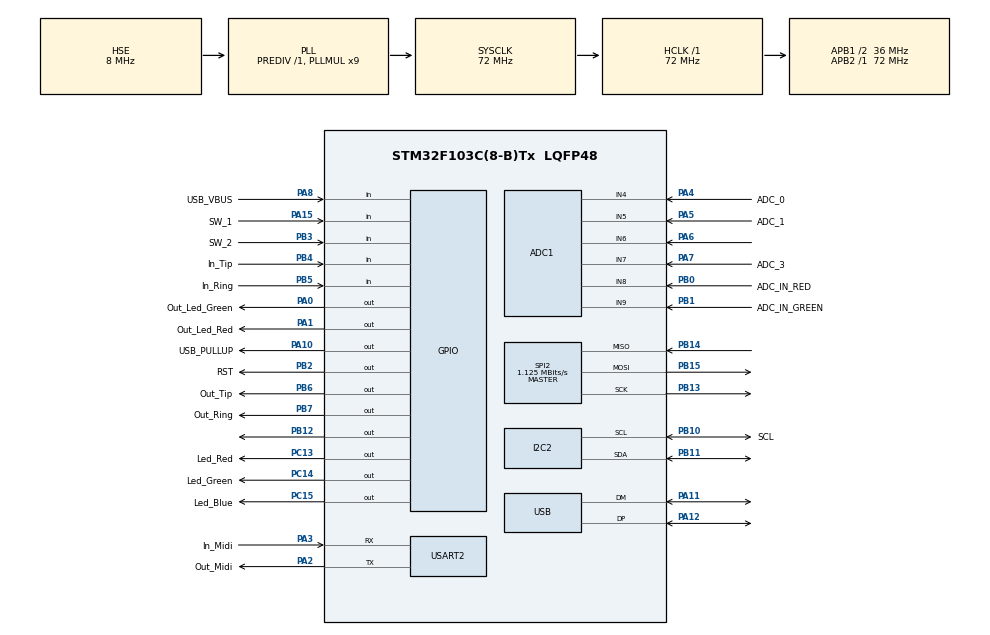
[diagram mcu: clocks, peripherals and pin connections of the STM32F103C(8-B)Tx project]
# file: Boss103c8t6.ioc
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Mcu.Family=STM32F1
USB_DEVICE.CLASS_NAME_FS=CDC
SPI2.VirtualType=VM_MASTER
PB10.Mode=I2C
ADC1.ContinuousConvMode=ENABLE
ADC1.SamplingTime-6\#ChannelRegularConversion=ADC_SAMPLETIME_239CYCLES_5
PA14.GPIO_Label=swdclk
PA11.Mode=Device
PB0.GPIO_Label=ADC_IN_RED
PB6.GPIO_Label=Out_Tip
PB11.Signal=I2C2_SDA
PB13.Signal=SPI2_SCK
PB15.Signal=SPI2_MOSI
PC15-OSC32_OUT.GPIO_Label=Led_Blue
RCC.SYSCLKSource=RCC_SYSCLKSOURCE_PLLCLK
ProjectManager.StackSize=0x400
PD1-OSC_OUT.Signal=RCC_OSC_OUT
PA15.GPIO_Label=SW_1
PA12.Signal=USB_DP
ADC1.Channel-5\#ChannelRegularConversion=ADC_CHANNEL_8
PA10.PinState=GPIO_PIN_SET
ADC1.Channel-3\#ChannelRegularConversion=ADC_CHANNEL_6
RCC.HCLKFreq_Value=72000000
RCC.APB2TimFreq_Value=72000000
PB6.Signal=GPIO_Output
Dma.ADC1.0.Direction=DMA_PERIPH_TO_MEMORY
ADC1.Channel-2\#ChannelRegularConversion=ADC_CHANNEL_5
Dma.ADC1.0.MemDataAlignment=DMA_MDATAALIGN_HALFWORD
RCC.AHBFreq_Value=72000000
SPI2.BaudRatePrescaler=SPI_BAUDRATEPRESCALER_32
PB2.Signal=GPIO_Output
RCC.PLLMUL=RCC_PLL_MUL9
ADC1.SamplingTime-4\#ChannelRegularConversion=ADC_SAMPLETIME_239CYCLES_5
ADC1.Channel-6\#ChannelRegularConversion=ADC_CHANNEL_9
PB3.GPIO_PuPd=GPIO_PULLUP
ADC1.Rank-2\#ChannelRegularConversion=2
PA14.Mode=Serial_Wire
PB14.Mode=Full_Duplex_Master
PB1.GPIO_Label=ADC_IN_GREEN
Dma.ADC1.0.PeriphInc=DMA_PINC_DISABLE
PA10.GPIO_Label=USB_PULLUP
SH.ADCx_IN8.0=ADC1_IN8,IN8
SPI2.CalculateBaudRate=1.125 MBits/s
PB7.Signal=GPIO_Output
PA8.Signal=GPIO_Input
TIM4.Period=65535
PB7.GPIO_Label=Out_Ring
Mcu.Package=LQFP48
PB1.Signal=ADCx_IN9
PA6.Signal=ADCx_IN6
SPI2.Mode=SPI_MODE_MASTER
USART2.VirtualMode=VM_ASYNC
PC13-TAMPER-RTC.GPIO_PuPd=GPIO_PULLUP
PA2.GPIO_Label=Out_Midi
PA10.Signal=GPIO_Output
PA15.Signal=GPIO_Input
SH.ADCx_IN9.0=ADC1_IN9,IN9
PB5.GPIO_Label=In_Ring
PC15-OSC32_OUT.GPIO_ModeDefaultOutputPP=GPIO_MODE_OUTPUT_OD
PC14-OSC32_IN.GPIO_ModeDefaultOutputPP=GPIO_MODE_OUTPUT_OD
RCC.APB1TimFreq_Value=72000000
PC14-OSC32_IN.GPIO_Label=Led_Green
SPI2.Direction=SPI_DIRECTION_2LINES
PB13.Mode=Full_Duplex_Master
ADC1.Rank-6\#ChannelRegularConversion=6
Dma.Request0=ADC1
PA4.GPIO_Label=ADC_0
ADC1.Rank-4\#ChannelRegularConversion=4
PB4.Signal=GPIO_Input
PA3.Signal=USART2_RX
PB3.GPIO_Label=SW_2
Dma.ADC1.0.Instance=DMA1_Channel1
PD1-OSC_OUT.Mode=HSE-External-Oscillator
ADC1.Channel-4\#ChannelRegularConversion=ADC_CHANNEL_7
USB_DEVICE.VirtualModeFS=Cdc_FS
SH.ADCx_IN6.0=ADC1_IN6,IN6
PC13-TAMPER-RTC.Signal=GPIO_Output
RCC.USBPrescaler=RCC_USBCLKSOURCE_PLL_DIV1_5
PD0-OSC_IN.Signal=RCC_OSC_IN
RCC.APB1CLKDivider=RCC_HCLK_DIV2
PC14-OSC32_IN.Signal=GPIO_Output
ADC1.SamplingTime-2\#ChannelRegularConversion=ADC_SAMPLETIME_239CYCLES_5
PA0-WKUP.GPIO_Label=Out_Led_Green
PA0-WKUP.Signal=GPIO_Output
RCC.ADCPresc=RCC_ADCPCLK2_DIV6
PA3.Mode=Asynchronous
PA13.Signal=SYS_JTMS-SWDIO
Dma.ADC1.0.PeriphDataAlignment=DMA_PDATAALIGN_HALFWORD
PA8.GPIO_Label=USB_VBUS
PB11.Mode=I2C
ProjectManager.TargetToolchain=STM32CubeIDE
PB10.GPIO_Label=SCL
SH.ADCx_IN7.0=ADC1_IN7,IN7
Dma.ADC1.0.Mode=DMA_CIRCULAR
VP_USB_DEVICE_VS_USB_DEVICE_CDC_FS.Mode=CDC_FS
Dma.ADC1.0.Priority=DMA_PRIORITY_LOW
ADC1.Channel-1\#ChannelRegularConversion=ADC_CHANNEL_4
RCC.USBFreq_Value=48000000
TIM4.Prescaler=35999
PC15-OSC32_OUT.Signal=GPIO_Output
PA1.Signal=GPIO_Output
PD0-OSC_IN.Mode=HSE-External-Oscillator
PB10.Signal=I2C2_SCL
PB14.Signal=SPI2_MISO
PA5.Signal=ADCx_IN5
board=custom
PC13-TAMPER-RTC.GPIO_Label=Led_Red
PB15.Mode=Full_Duplex_Master
RCC.APB2Freq_Value=72000000
PB4.GPIO_Label=In_Tip
NVIC.USB_LP_CAN1_RX0_IRQn=true\:0\:0\:false\:false\:true\:false\:true
PA1.GPIO_Label=Out_Led_Red
SH.ADCx_IN4.0=ADC1_IN4,IN4
PC15-OSC32_OUT.GPIO_PuPd=GPIO_PULLUP
ADC1.NbrOfConversion=6
PA13.Mode=Serial_Wire
Mcu.Name=STM32F103C(8-B)Tx
PA2.Signal=USART2_TX
PA13.GPIO_Label=swdio
PB3.Signal=GPIO_Input
PA4.Signal=ADCx_IN4
ADC1.SamplingTime-1\#ChannelRegularConversion=ADC_SAMPLETIME_239CYCLES_5
RCC.SYSCLKFreq_VALUE=72000000
PC13-TAMPER-RTC.GPIO_ModeDefaultOutputPP=GPIO_MODE_OUTPUT_OD
PB5.Signal=GPIO_Input
PA7.GPIO_Label=ADC_3
ADC1.master=1
PA12.Mode=Device
PA5.GPIO_Label=ADC_1
ADC1.Rank-3\#ChannelRegularConversion=3
ADC1.SamplingTime-3\#ChannelRegularConversion=ADC_SAMPLETIME_239CYCLES_5
ADC1.Rank-1\#ChannelRegularConversion=1
PA11.Signal=USB_DM
PA14.Signal=SYS_JTCK-SWCLK
Dma.ADC1.0.MemInc=DMA_MINC_ENABLE
PB2.GPIO_Label=RST
ProjectManager.HeapSize=0x200
ADC1.SamplingTime-5\#ChannelRegularConversion=ADC_SAMPLETIME_239CYCLES_5
SH.ADCx_IN5.0=ADC1_IN5,IN5
VP_TIM4_VS_ClockSourceINT.Mode=Internal
NVIC.PriorityGroup=NVIC_PRIORITYGROUP_4
ADC1.NbrOfConversionFlag=1
PA15.GPIO_PuPd=GPIO_PULLUP
PA2.Mode=Asynchronous
PC14-OSC32_IN.GPIO_PuPd=GPIO_PULLUP
NVIC.DMA1_Channel1_IRQn=true\:0\:0\:false\:false\:true\:false\:true
ADC1.DataAlign=ADC_DATAALIGN_LEFT
RCC.APB1Freq_Value=36000000
PB0.Signal=ADCx_IN8
USB_DEVICE.VirtualMode=Cdc
ADC1.Rank-5\#ChannelRegularConversion=5
PB12.Signal=GPIO_Output
PA3.GPIO_Label=In_Midi
PA7.Signal=ADCx_IN7

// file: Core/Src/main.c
/* USER CODE BEGIN Header */
/**
  ******************************************************************************
  * @file           : main.c
  * @brief          : Main program body
  ******************************************************************************
  * @attention
  *
  * <h2><center>&copy; Copyright (c) 2023 STMicroelectronics.
  * All rights reserved.</center></h2>
  *
  * This software component is licensed by ST under Ultimate Liberty license
  * SLA0044, the "License"; You may not use this file except in compliance with
  * the License. You may obtain a copy of the License at:
  *                             www.st.com/SLA0044
  *
  ******************************************************************************
  */
/* USER CODE END Header */
#include "main.h"
#include "usb_device.h"

/* USER CODE BEGIN Includes */
#include "ProjectMain.h"
/* USER CODE END Includes */

ADC_HandleTypeDef hadc1;
DMA_HandleTypeDef hdma_adc1;

I2C_HandleTypeDef hi2c2;

SPI_HandleTypeDef hspi2;

TIM_HandleTypeDef htim4;

UART_HandleTypeDef huart2;

void SystemClock_Config(void);
static void MX_GPIO_Init(void);
static void MX_DMA_Init(void);
static void MX_USART2_UART_Init(void);
static void MX_ADC1_Init(void);
static void MX_SPI2_Init(void);
static void MX_I2C2_Init(void);
static void MX_TIM4_Init(void);

int main(void)
{

  /* MCU Configuration--------------------------------------------------------*/

  /* Reset of all peripherals, Initializes the Flash interface and the Systick. */
  HAL_Init();

  /* Configure the system clock */
  SystemClock_Config();

  /* Initialize all configured peripherals */
  MX_GPIO_Init();
  MX_DMA_Init();
  MX_USART2_UART_Init();
  MX_ADC1_Init();
  MX_SPI2_Init();
  MX_USB_DEVICE_Init();
  MX_I2C2_Init();
  MX_TIM4_Init();
  /* USER CODE BEGIN 2 */
  while(HAL_ADCEx_Calibration_Start(&hadc1) != HAL_OK);							// калибровка и запуск АЦП
  HAL_ADC_Start_DMA(&hadc1, (uint32_t *) Adc1ConvertedValue, ADC_NUM_CHANNELS);
  ProjectMain();																// Основной цикл
  /* USER CODE END 2 */

  /* Infinite loop */
  while (1)
  {

  }
}

void SystemClock_Config(void)
{
  RCC_OscInitTypeDef RCC_OscInitStruct = {0};
  RCC_ClkInitTypeDef RCC_ClkInitStruct = {0};
  RCC_PeriphCLKInitTypeDef PeriphClkInit = {0};

  /** Initializes the RCC Oscillators according to the specified parameters
  * in the RCC_OscInitTypeDef structure.
  */
  RCC_OscInitStruct.OscillatorType = RCC_OSCILLATORTYPE_HSE;
  RCC_OscInitStruct.HSEState = RCC_HSE_ON;
  RCC_OscInitStruct.HSEPredivValue = RCC_HSE_PREDIV_DIV1;
  RCC_OscInitStruct.HSIState = RCC_HSI_ON;
  RCC_OscInitStruct.PLL.PLLState = RCC_PLL_ON;
  RCC_OscInitStruct.PLL.PLLSource = RCC_PLLSOURCE_HSE;
  RCC_OscInitStruct.PLL.PLLMUL = RCC_PLL_MUL9;
  if (HAL_RCC_OscConfig(&RCC_OscInitStruct) != HAL_OK)
  {
    Error_Handler();
  }
  /** Initializes the CPU, AHB and APB buses clocks
  */
  RCC_ClkInitStruct.ClockType = RCC_CLOCKTYPE_HCLK|RCC_CLOCKTYPE_SYSCLK
                              |RCC_CLOCKTYPE_PCLK1|RCC_CLOCKTYPE_PCLK2;
  RCC_ClkInitStruct.SYSCLKSource = RCC_SYSCLKSOURCE_PLLCLK;
  RCC_ClkInitStruct.AHBCLKDivider = RCC_SYSCLK_DIV1;
  RCC_ClkInitStruct.APB1CLKDivider = RCC_HCLK_DIV2;
  RCC_ClkInitStruct.APB2CLKDivider = RCC_HCLK_DIV1;

  if (HAL_RCC_ClockConfig(&RCC_ClkInitStruct, FLASH_LATENCY_2) != HAL_OK)
  {
    Error_Handler();
  }
  PeriphClkInit.PeriphClockSelection = RCC_PERIPHCLK_ADC|RCC_PERIPHCLK_USB;
  PeriphClkInit.AdcClockSelection = RCC_ADCPCLK2_DIV6;
  PeriphClkInit.UsbClockSelection = RCC_USBCLKSOURCE_PLL_DIV1_5;
  if (HAL_RCCEx_PeriphCLKConfig(&PeriphClkInit) != HAL_OK)
  {
    Error_Handler();
  }
}

static void MX_ADC1_Init(void)
{

  ADC_ChannelConfTypeDef sConfig = {0};

  /** Common config
  */
  hadc1.Instance = ADC1;
  hadc1.Init.ScanConvMode = ADC_SCAN_ENABLE;
  hadc1.Init.ContinuousConvMode = ENABLE;
  hadc1.Init.DiscontinuousConvMode = DISABLE;
  hadc1.Init.ExternalTrigConv = ADC_SOFTWARE_START;
  hadc1.Init.DataAlign = ADC_DATAALIGN_LEFT;
  hadc1.Init.NbrOfConversion = 6;
  if (HAL_ADC_Init(&hadc1) != HAL_OK)
  {
    Error_Handler();
  }
  /** Configure Regular Channel
  */
  sConfig.Channel = ADC_CHANNEL_4;
  sConfig.Rank = ADC_REGULAR_RANK_1;
  sConfig.SamplingTime = ADC_SAMPLETIME_239CYCLES_5;
  if (HAL_ADC_ConfigChannel(&hadc1, &sConfig) != HAL_OK)
  {
    Error_Handler();
  }
  /** Configure Regular Channel
  */
  sConfig.Channel = ADC_CHANNEL_5;
  sConfig.Rank = ADC_REGULAR_RANK_2;
  if (HAL_ADC_ConfigChannel(&hadc1, &sConfig) != HAL_OK)
  {
    Error_Handler();
  }
  /** Configure Regular Channel
  */
  sConfig.Channel = ADC_CHANNEL_6;
  sConfig.Rank = ADC_REGULAR_RANK_3;
  if (HAL_ADC_ConfigChannel(&hadc1, &sConfig) != HAL_OK)
  {
    Error_Handler();
  }
  /** Configure Regular Channel
  */
  sConfig.Channel = ADC_CHANNEL_7;
  sConfig.Rank = ADC_REGULAR_RANK_4;
  if (HAL_ADC_ConfigChannel(&hadc1, &sConfig) != HAL_OK)
  {
    Error_Handler();
  }
  /** Configure Regular Channel
  */
  sConfig.Channel = ADC_CHANNEL_8;
  sConfig.Rank = ADC_REGULAR_RANK_5;
  if (HAL_ADC_ConfigChannel(&hadc1, &sConfig) != HAL_OK)
  {
    Error_Handler();
  }
  /** Configure Regular Channel
  */
  sConfig.Channel = ADC_CHANNEL_9;
  sConfig.Rank = ADC_REGULAR_RANK_6;
  if (HAL_ADC_ConfigChannel(&hadc1, &sConfig) != HAL_OK)
  {
    Error_Handler();
  }

}

static void MX_I2C2_Init(void)
{

  hi2c2.Instance = I2C2;
  hi2c2.Init.ClockSpeed = 100000;
  hi2c2.Init.DutyCycle = I2C_DUTYCYCLE_2;
  hi2c2.Init.OwnAddress1 = 0;
  hi2c2.Init.AddressingMode = I2C_ADDRESSINGMODE_7BIT;
  hi2c2.Init.DualAddressMode = I2C_DUALADDRESS_DISABLE;
  hi2c2.Init.OwnAddress2 = 0;
  hi2c2.Init.GeneralCallMode = I2C_GENERALCALL_DISABLE;
  hi2c2.Init.NoStretchMode = I2C_NOSTRETCH_DISABLE;
  if (HAL_I2C_Init(&hi2c2) != HAL_OK)
  {
    Error_Handler();
  }

}

static void MX_SPI2_Init(void)
{

  /* SPI2 parameter configuration*/
  hspi2.Instance = SPI2;
  hspi2.Init.Mode = SPI_MODE_MASTER;
  hspi2.Init.Direction = SPI_DIRECTION_2LINES;
  hspi2.Init.DataSize = SPI_DATASIZE_8BIT;
  hspi2.Init.CLKPolarity = SPI_POLARITY_LOW;
  hspi2.Init.CLKPhase = SPI_PHASE_1EDGE;
  hspi2.Init.NSS = SPI_NSS_SOFT;
  hspi2.Init.BaudRatePrescaler = SPI_BAUDRATEPRESCALER_32;
  hspi2.Init.FirstBit = SPI_FIRSTBIT_MSB;
  hspi2.Init.TIMode = SPI_TIMODE_DISABLE;
  hspi2.Init.CRCCalculation = SPI_CRCCALCULATION_DISABLE;
  hspi2.Init.CRCPolynomial = 10;
  if (HAL_SPI_Init(&hspi2) != HAL_OK)
  {
    Error_Handler();
  }

}

static void MX_TIM4_Init(void)
{

  TIM_ClockConfigTypeDef sClockSourceConfig = {0};
  TIM_MasterConfigTypeDef sMasterConfig = {0};

  htim4.Instance = TIM4;
  htim4.Init.Prescaler = 35999;
  htim4.Init.CounterMode = TIM_COUNTERMODE_UP;
  htim4.Init.Period = 65535;
//  htim4.Init.Period = 65533;
  htim4.Init.ClockDivision = TIM_CLOCKDIVISION_DIV1;
  htim4.Init.AutoReloadPreload = TIM_AUTORELOAD_PRELOAD_DISABLE;
  if (HAL_TIM_Base_Init(&htim4) != HAL_OK)
  {
    Error_Handler();
  }
  sClockSourceConfig.ClockSource = TIM_CLOCKSOURCE_INTERNAL;
  if (HAL_TIM_ConfigClockSource(&htim4, &sClockSourceConfig) != HAL_OK)
  {
    Error_Handler();
  }
  sMasterConfig.MasterOutputTrigger = TIM_TRGO_RESET;
  sMasterConfig.MasterSlaveMode = TIM_MASTERSLAVEMODE_DISABLE;
  if (HAL_TIMEx_MasterConfigSynchronization(&htim4, &sMasterConfig) != HAL_OK)
  {
    Error_Handler();
  }

}

static void MX_USART2_UART_Init(void)
{

  huart2.Instance = USART2;
  huart2.Init.BaudRate = 115200;
  huart2.Init.WordLength = UART_WORDLENGTH_8B;
  huart2.Init.StopBits = UART_STOPBITS_1;
  huart2.Init.Parity = UART_PARITY_NONE;
  huart2.Init.Mode = UART_MODE_TX_RX;
  huart2.Init.HwFlowCtl = UART_HWCONTROL_NONE;
  huart2.Init.OverSampling = UART_OVERSAMPLING_16;
  if (HAL_UART_Init(&huart2) != HAL_OK)
  {
    Error_Handler();
  }

}

static void MX_DMA_Init(void)
{

  /* DMA controller clock enable */
  __HAL_RCC_DMA1_CLK_ENABLE();

  /* DMA interrupt init */
  /* DMA1_Channel1_IRQn interrupt configuration */
  HAL_NVIC_SetPriority(DMA1_Channel1_IRQn, 0, 0);
  HAL_NVIC_EnableIRQ(DMA1_Channel1_IRQn);

}

static void MX_GPIO_Init(void)
{
  GPIO_InitTypeDef GPIO_InitStruct = {0};

  /* GPIO Ports Clock Enable */
  __HAL_RCC_GPIOC_CLK_ENABLE();
  __HAL_RCC_GPIOD_CLK_ENABLE();
  __HAL_RCC_GPIOA_CLK_ENABLE();
  __HAL_RCC_GPIOB_CLK_ENABLE();

  /*Configure GPIO pin Output Level */
  HAL_GPIO_WritePin(GPIOC, Led_Red_Pin|Led_Green_Pin|Led_Blue_Pin, GPIO_PIN_RESET);

  /*Configure GPIO pin Output Level */
  HAL_GPIO_WritePin(GPIOA, Out_Led_Green_Pin|Out_Led_Red_Pin, GPIO_PIN_RESET);

  /*Configure GPIO pin Output Level */
  HAL_GPIO_WritePin(GPIOB, RST_Pin|GPIO_PIN_12|Out_Tip_Pin|Out_Ring_Pin, GPIO_PIN_RESET);

  /*Configure GPIO pin Output Level */
  HAL_GPIO_WritePin(USB_PULLUP_GPIO_Port, USB_PULLUP_Pin, GPIO_PIN_SET);

  /*Configure GPIO pins : Led_Red_Pin Led_Green_Pin Led_Blue_Pin */
  GPIO_InitStruct.Pin = Led_Red_Pin|Led_Green_Pin|Led_Blue_Pin;
  GPIO_InitStruct.Mode = GPIO_MODE_OUTPUT_OD;
  GPIO_InitStruct.Pull = GPIO_PULLUP;
  GPIO_InitStruct.Speed = GPIO_SPEED_FREQ_LOW;
  HAL_GPIO_Init(GPIOC, &GPIO_InitStruct);

  /*Configure GPIO pins : Out_Led_Green_Pin Out_Led_Red_Pin USB_PULLUP_Pin */
  GPIO_InitStruct.Pin = Out_Led_Green_Pin|Out_Led_Red_Pin|USB_PULLUP_Pin;
  GPIO_InitStruct.Mode = GPIO_MODE_OUTPUT_PP;
  GPIO_InitStruct.Pull = GPIO_NOPULL;
  GPIO_InitStruct.Speed = GPIO_SPEED_FREQ_LOW;
  HAL_GPIO_Init(GPIOA, &GPIO_InitStruct);

  /*Configure GPIO pins : RST_Pin PB12 Out_Tip_Pin Out_Ring_Pin */
  GPIO_InitStruct.Pin = RST_Pin|GPIO_PIN_12|Out_Tip_Pin|Out_Ring_Pin;
  GPIO_InitStruct.Mode = GPIO_MODE_OUTPUT_PP;
  GPIO_InitStruct.Pull = GPIO_NOPULL;
  GPIO_InitStruct.Speed = GPIO_SPEED_FREQ_LOW;
  HAL_GPIO_Init(GPIOB, &GPIO_InitStruct);

  /*Configure GPIO pin : USB_VBUS_Pin */
  GPIO_InitStruct.Pin = USB_VBUS_Pin;
  GPIO_InitStruct.Mode = GPIO_MODE_INPUT;
  GPIO_InitStruct.Pull = GPIO_NOPULL;
  HAL_GPIO_Init(USB_VBUS_GPIO_Port, &GPIO_InitStruct);

  /*Configure GPIO pin : SW_1_Pin */
  GPIO_InitStruct.Pin = SW_1_Pin;
  GPIO_InitStruct.Mode = GPIO_MODE_INPUT;
  GPIO_InitStruct.Pull = GPIO_PULLUP;
  HAL_GPIO_Init(SW_1_GPIO_Port, &GPIO_InitStruct);

  /*Configure GPIO pin : SW_2_Pin */
  GPIO_InitStruct.Pin = SW_2_Pin;
  GPIO_InitStruct.Mode = GPIO_MODE_INPUT;
  GPIO_InitStruct.Pull = GPIO_PULLUP;
  HAL_GPIO_Init(SW_2_GPIO_Port, &GPIO_InitStruct);

  /*Configure GPIO pins : In_Tip_Pin In_Ring_Pin */
  GPIO_InitStruct.Pin = In_Tip_Pin|In_Ring_Pin;
  GPIO_InitStruct.Mode = GPIO_MODE_INPUT;
  GPIO_InitStruct.Pull = GPIO_NOPULL;
  HAL_GPIO_Init(GPIOB, &GPIO_InitStruct);

}

void Error_Handler(void)
{
  __disable_irq();
  while (1)
  {
  }
}

/************************ (C) COPYRIGHT STMicroelectronics *****END OF FILE****/
